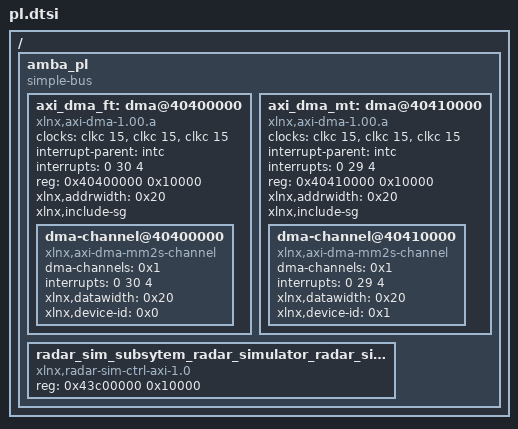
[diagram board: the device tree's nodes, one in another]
/*
 * CAUTION: This file is automatically generated by Xilinx.
 * Version:  
 * Today is: Sun Jan 22 19:02:08 2017
*/


/ {
	amba_pl: amba_pl {
		#address-cells = <1>;
		#size-cells = <1>;
		compatible = "simple-bus";
		ranges ;
		axi_dma_ft: dma@40400000 {
			#dma-cells = <1>;
			clock-names = "s_axi_lite_aclk", "m_axi_sg_aclk", "m_axi_mm2s_aclk";
			clocks = <&clkc 15>, <&clkc 15>, <&clkc 15>;
			compatible = "xlnx,axi-dma-1.00.a";
			interrupt-parent = <&intc>;
			interrupts = <0 30 4>;
			reg = <0x40400000 0x10000>;
			xlnx,addrwidth = <0x20>;
			xlnx,include-sg ;
			dma-channel@40400000 {
				compatible = "xlnx,axi-dma-mm2s-channel";
				dma-channels = <0x1>;
				interrupts = <0 30 4>;
				xlnx,datawidth = <0x20>;
				xlnx,device-id = <0x0>;
			};
		};
		axi_dma_mt: dma@40410000 {
			#dma-cells = <1>;
			clock-names = "s_axi_lite_aclk", "m_axi_sg_aclk", "m_axi_mm2s_aclk";
			clocks = <&clkc 15>, <&clkc 15>, <&clkc 15>;
			compatible = "xlnx,axi-dma-1.00.a";
			interrupt-parent = <&intc>;
			interrupts = <0 29 4>;
			reg = <0x40410000 0x10000>;
			xlnx,addrwidth = <0x20>;
			xlnx,include-sg ;
			dma-channel@40410000 {
				compatible = "xlnx,axi-dma-mm2s-channel";
				dma-channels = <0x1>;
				interrupts = <0 29 4>;
				xlnx,datawidth = <0x20>;
				xlnx,device-id = <0x1>;
			};
		};
		radar_sim_subsytem_radar_simulator_radar_sim_ctrl_axi_0: radar_sim_ctrl_axi@43c00000 {
			compatible = "xlnx,radar-sim-ctrl-axi-1.0";
			reg = <0x43c00000 0x10000>;
		};
	};
};
